# STM32F103 register map
File version: 1.1
CPU: CM3 r1p1, little endian, no MPU, no FPU, 4 interrupt priority bits
Registers are 32-bit, read-write, reset 0x0 unless marked. A register's access mark holds for its fields unless they carry their own. Offsets are from the block's base; [hi:lo] are bit positions; lines under a group give offsets from that group; {n}, {i} and the like mark numbered series; 'fields as' and 'values as' point back to an identical list.

## ADC1 — Analog to digital converter
Base 0x40012400
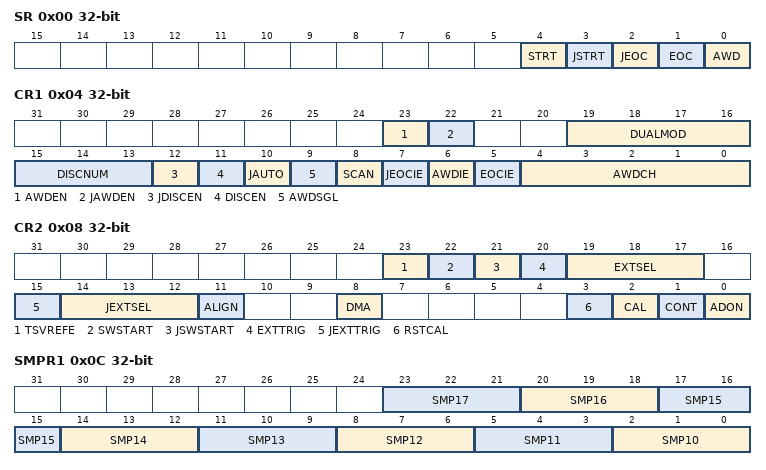
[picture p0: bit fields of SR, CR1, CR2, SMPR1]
0x00 SR — status register
  [4] STRT write-0-clears — Regular channel start flag
    on read: 0=NotStarted (No regular channel conversion started); 1=Started (Regular channel conversion has started) | on write: 0=Clear the Regular channel Start flag
  [3] JSTRT write-0-clears — Injected channel start flag
    on read: 0=NotStarted (No injected group conversion started); 1=Started (Injected group conversion has started) | on write: 0=Clear Injected channel Start flag
  [2] JEOC write-0-clears — Injected channel end of conversion
    on read: 0=NotComplete (Conversion is not complete); 1=Complete (Conversion complete) | on write: 0=Clear Injected channel end of conversion flag
  [1] EOC write-0-clears — Regular channel end of conversion
    on read: 0=NotComplete (Conversion is not complete); 1=Complete (Conversion complete) | on write: 0=Clear End of conversion flag
  [0] AWD write-0-clears — Analog watchdog flag
    on read: 0=NoEvent (No analog watchdog event occurred); 1=Event (Analog watchdog event occurred) | on write: 0=Clear the analog watchdog event flag
0x04 CR1 — control register 1
  [23] AWDEN — Analog watchdog enable on regular channels
    0=Disabled (Analog watchdog disabled on regular channels); 1=Enabled (Analog watchdog enabled on regular channels)
  [22] JAWDEN — Analog watchdog enable on injected channels
    0=Disabled (Analog watchdog disabled on injected channels); 1=Enabled (Analog watchdog enabled on injected channels)
  [19:16] DUALMOD — Dual mode selection
    0=Independent mode; 1=RegularInjected (Combined regular simultaneous + injected simultaneous mode); 2=RegularAlternateTrigger (Combined regular simultaneous + alternate trigger mode); 3=InjectedFastInterleaved (Combined injected simultaneous + fast interleaved mode); 4=InjectedSlowInterleaved (Combined injected simultaneous + slow interleaved mode); 5=Injected simultaneous mode only; 6=Regular simultaneous mode only; 7=Fast interleaved mode only; 8=Slow interleaved mode only; 9=Alternate trigger mode only
  [15:13] DISCNUM — Discontinuous mode channel count
  [12] JDISCEN — Discontinuous mode on injected channels
    0=Disabled (Discontinuous mode on injected channels disabled); 1=Enabled (Discontinuous mode on injected channels enabled)
  [11] DISCEN — Discontinuous mode on regular channels
    0=Disabled (Discontinuous mode on regular channels disabled); 1=Enabled (Discontinuous mode on regular channels enabled)
  [10] JAUTO — Automatic injected group conversion
    0=Disabled (Automatic injected group conversion disabled); 1=Enabled (Automatic injected group conversion enabled)
  [9] AWDSGL — Enable the watchdog on a single channel in scan mode
    0=All (Analog watchdog enabled on all channels); 1=Single (Analog watchdog enabled on a single channel)
  [8] SCAN — Scan mode
    0=Disabled (Scan mode disabled); 1=Enabled (Scan mode enabled)
  [7] JEOCIE — Interrupt enable for injected channels
    0=Disabled (JEOC interrupt disabled); 1=Enabled (JEOC interrupt enabled. An interrupt is generated when the JEOC bit is set)
  [6] AWDIE — Analog watchdog interrupt enable
    0=Disabled (Analog watchdog interrupt disabled); 1=Enabled (Analog watchdog interrupt enabled)
  [5] EOCIE — Interrupt enable for EOC
    0=Disabled (EOC interrupt disabled); 1=Enabled (EOC interrupt enabled. An interrupt is generated when the EOC bit is set)
  [4:0] AWDCH range 0..17 — Analog watchdog channel select bits
0x08 CR2 — control register 2
  [23] TSVREFE — Temperature sensor and VREFINT enable
    0=Disabled (Temperature sensor and V_REFINT channel disabled); 1=Enabled (Temperature sensor and V_REFINT channel enabled)
  [22] SWSTART — Start conversion of regular channels
    on read: 0=Started (Reset state); 1=NotStarted (Starting conversion of regular channels) | on write: 1=Start conversion of regular channels
  [21] JSWSTART — Start conversion of injected channels
    on read: 0=Started (Reset state); 1=NotStarted (Starting conversion of injected channels) | on write: 1=Start conversion of injected channels
  [20] EXTTRIG — External trigger conversion mode for regular channels
    0=Disabled (Conversion on external event disabled); 1=Enabled (Conversion on external event enabled)
  [19:17] EXTSEL — External event select for regular group
    0=Tim1Cc1 (Timer 1 CC1 event); 1=Tim1Cc2 (Timer 1 CC2 event); 2=Tim1Cc3 (Timer 1 CC3 event); 3=Tim2Cc2 (Timer 2 CC2 event); 4=Tim3Trgo (Timer 3 TRGO event); 5=Tim4Cc4 (Timer 4 CC4 event); 6=Exti11 (EXTI line 11/TIM8_TRGO event (TIM8_TRGO is available only in high-density and XL-density devices)); 7=Swstart
  [15] JEXTTRIG — External trigger conversion mode for injected channels
    values as EXTTRIG
  [14:12] JEXTSEL — External event select for injected group
    0=Tim1Trgo (Timer 1 TRGO event); 1=Tim1Cc4 (Timer 1 CC4 event); 2=Tim2Trgo (Timer 2 TRGO event); 3=Tim2Cc1 (Timer 2 CC1 event); 4=Tim3Cc4 (Timer 3 CC4 event); 5=Tim4Trgo (Timer 4 TRGO event); 6=Exti15 (EXTI line15/TIM8_CC4 event (TIM8_CC4 is available only in high-density and XL-density devices)); 7=Jswstart
  [11] ALIGN — Data alignment
    0=Right Alignment; 1=Left Alignment
  [8] DMA — Direct memory access mode
    0=Disabled (DMA mode disabled); 1=Enabled (DMA mode enabled)
  [3] RSTCAL — Reset calibration
    on read: 0=Initialized (Calibration register initialized); 1=NotInitialized (Initializing calibration register) | on write: 1=Initialize calibration register
  [2] CAL — A/D calibration
    on read: 0=Complete (Calibration completed); 1=NotComplete (Calibrating) | on write: 1=Start (Enable calibration)
  [1] CONT — Continuous conversion
    0=Single conversion mode; 1=Continuous conversion mode
  [0] ADON — A/D converter ON / OFF
    0=Disabled (Disable ADC conversion/calibration and go to power down mode); 1=Enabled (Enable ADC and to start conversion)
0x0C SMPR1 — sample time register 1
  [3n-28:3n-30] SMP{n} (n=10..17) — Channel {n} sample time selection
    0=Cycles1_5 (1.5 ADC clock cycles); 1=Cycles7_5 (7.5 ADC clock cycles); 2=Cycles13_5 (13.5 ADC clock cycles); 3=Cycles28_5 (28.5 ADC clock cycles); 4=Cycles41_5 (41.5 ADC clock cycles); 5=Cycles55_5 (55.5 ADC clock cycles); 6=Cycles71_5 (71.5 ADC clock cycles); 7=Cycles239_5 (239.5 ADC clock cycles)
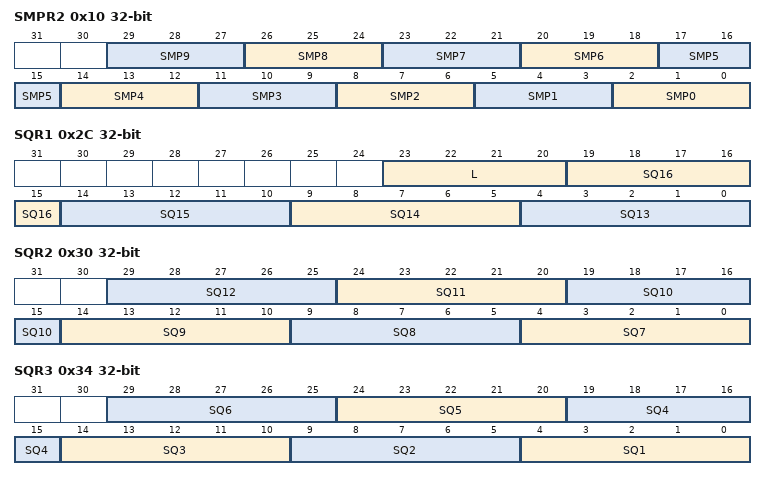
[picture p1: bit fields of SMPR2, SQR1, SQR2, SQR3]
0x10 SMPR2 — sample time register 2
  [3n+2:3n] SMP{n} (n=0..9) — Channel {n} sample time selection
    values as SMPR1.SMP10
{0x10+4i} JOFR{i} (i=1..4) — injected channel data offset register {i}
  [11:0] JOFFSET — Data offset for injected channel
0x24 HTR reset 0xFFF — watchdog higher threshold register
  [11:0] HT — Analog watchdog higher threshold
0x28 LTR — watchdog lower threshold register
  [11:0] LT — Analog watchdog lower threshold
0x2C SQR1 — regular sequence register 1
  [23:20] L — Regular channel sequence length
  [5n-61:5n-65] SQ{n} (n=13..16) range 0..17 — {n} conversion in regular sequence
0x30 SQR2 — regular sequence register 2
  [5n-31:5n-35] SQ{n} (n=7..12) range 0..17 — {n} conversion in regular sequence
0x34 SQR3 — regular sequence register 3
  [5n-1:5n-5] SQ{n} (n=1..6) range 0..17 — {n} conversion in regular sequence
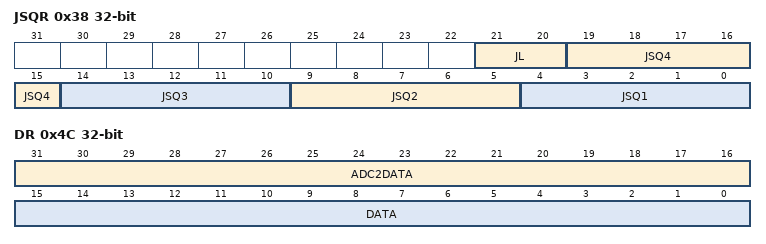
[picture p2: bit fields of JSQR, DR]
0x38 JSQR — injected sequence register
  [21:20] JL — Injected sequence length
  [5n-1:5n-5] JSQ{n} (n=1..4) range 0..17 — {n} conversion in injected sequence
{0x38+4i} JDR{i} (i=1..4) ro — injected data register x
  [15:0] JDATA — Injected data
0x4C DR ro — regular data register
  [31:16] ADC2DATA
  [15:0] DATA — Regular data

## ADC2 — Analog to digital converter
Base 0x40012800
Registers as ADC1; these are added or differ:
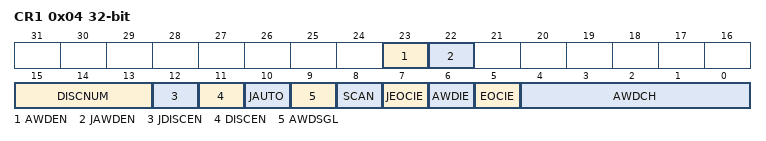
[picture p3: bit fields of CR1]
0x04 CR1 — control register 1
  [23] AWDEN — Analog watchdog enable on regular channels
    0=Disabled (Analog watchdog disabled on regular channels); 1=Enabled (Analog watchdog enabled on regular channels)
  [22] JAWDEN — Analog watchdog enable on injected channels
    0=Disabled (Analog watchdog disabled on injected channels); 1=Enabled (Analog watchdog enabled on injected channels)
  [15:13] DISCNUM — Discontinuous mode channel count
  [12] JDISCEN — Discontinuous mode on injected channels
    0=Disabled (Discontinuous mode on injected channels disabled); 1=Enabled (Discontinuous mode on injected channels enabled)
  [11] DISCEN — Discontinuous mode on regular channels
    0=Disabled (Discontinuous mode on regular channels disabled); 1=Enabled (Discontinuous mode on regular channels enabled)
  [10] JAUTO — Automatic injected group conversion
    0=Disabled (Automatic injected group conversion disabled); 1=Enabled (Automatic injected group conversion enabled)
  [9] AWDSGL — Enable the watchdog on a single channel in scan mode
    0=All (Analog watchdog enabled on all channels); 1=Single (Analog watchdog enabled on a single channel)
  [8] SCAN — Scan mode
    0=Disabled (Scan mode disabled); 1=Enabled (Scan mode enabled)
  [7] JEOCIE — Interrupt enable for injected channels
    0=Disabled (JEOC interrupt disabled); 1=Enabled (JEOC interrupt enabled. An interrupt is generated when the JEOC bit is set)
  [6] AWDIE — Analog watchdog interrupt enable
    0=Disabled (Analog watchdog interrupt disabled); 1=Enabled (Analog watchdog interrupt enabled)
  [5] EOCIE — Interrupt enable for EOC
    0=Disabled (EOC interrupt disabled); 1=Enabled (EOC interrupt enabled. An interrupt is generated when the EOC bit is set)
  [4:0] AWDCH range 0..17 — Analog watchdog channel select bits
0x4C DR ro — regular data register
  [15:0] DATA — Regular data

## ADC3 — Analog to digital converter
Base 0x40013C00
Registers as ADC2; these are added or differ:
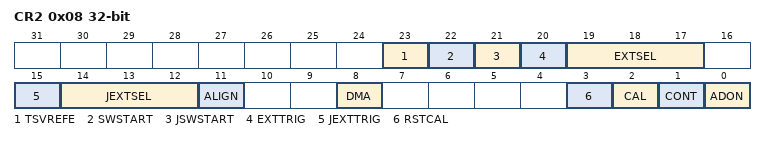
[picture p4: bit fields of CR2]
0x08 CR2 — control register 2
  [23] TSVREFE — Temperature sensor and VREFINT enable
    0=Disabled (Temperature sensor and V_REFINT channel disabled); 1=Enabled (Temperature sensor and V_REFINT channel enabled)
  [22] SWSTART — Start conversion of regular channels
    on read: 0=Started (Reset state); 1=NotStarted (Starting conversion of regular channels) | on write: 1=Start conversion of regular channels
  [21] JSWSTART — Start conversion of injected channels
    on read: 0=Started (Reset state); 1=NotStarted (Starting conversion of injected channels) | on write: 1=Start conversion of injected channels
  [20] EXTTRIG — External trigger conversion mode for regular channels
    0=Disabled (Conversion on external event disabled); 1=Enabled (Conversion on external event enabled)
  [19:17] EXTSEL — External event select for regular group
    0=Tim3Cc1 (Timer 3 CC1 event); 1=Tim2Cc3 (Timer 2 CC3 event); 2=Tim1Cc3 (Timer 1 CC3 event); 3=Tim8Cc1 (Timer 8 CC1 event); 4=Tim8Trgo (Timer 8 TRGO event); 5=Tim5Cc1 (Timer 5 CC1 event); 6=Tim5Cc3 (Timer 5 CC3 event); 7=Swstart
  [15] JEXTTRIG — External trigger conversion mode for injected channels
    values as EXTTRIG
  [14:12] JEXTSEL — External event select for injected group
    0=Tim1Trgo (Timer 1 TRGO event); 1=Tim1Cc4 (Timer 1 CC4 event); 2=Tim4Cc3 (Timer 4 CC3 event); 3=Tim8Cc2 (Timer 8 CC2 event); 4=Tim8Cc4 (Timer 8 CC4 event); 5=Tim5Trgo (Timer 5 TRGO event); 6=Tim5Cc4 (Timer 5 CC4 event); 7=Jswstart
  [11] ALIGN — Data alignment
    0=Right Alignment; 1=Left Alignment
  [8] DMA — Direct memory access mode
    0=Disabled (DMA mode disabled); 1=Enabled (DMA mode enabled)
  [3] RSTCAL — Reset calibration
    on read: 0=Initialized (Calibration register initialized); 1=NotInitialized (Initializing calibration register) | on write: 1=Initialize calibration register
  [2] CAL — A/D calibration
    on read: 0=Complete (Calibration completed); 1=NotComplete (Calibrating) | on write: 1=Start (Enable calibration)
  [1] CONT — Continuous conversion
    0=Single conversion mode; 1=Continuous conversion mode
  [0] ADON — A/D converter ON / OFF
    0=Disabled (Disable ADC conversion/calibration and go to power down mode); 1=Enabled (Enable ADC and to start conversion)
